# STM32F302 register map
File version: 1.8
CPU: CM4 r1p0, little endian, MPU, FPU, 4 interrupt priority bits
Registers are 32-bit, read-write, reset 0x0 unless marked. A register's access mark holds for its fields unless they carry their own. Offsets are from the block's base; [hi:lo] are bit positions; lines under a group give offsets from that group; {n}, {i} and the like mark numbered series; 'fields as' and 'values as' point back to an identical list; <NAME> marks a mode.

## FLASH
Base 0x40022000
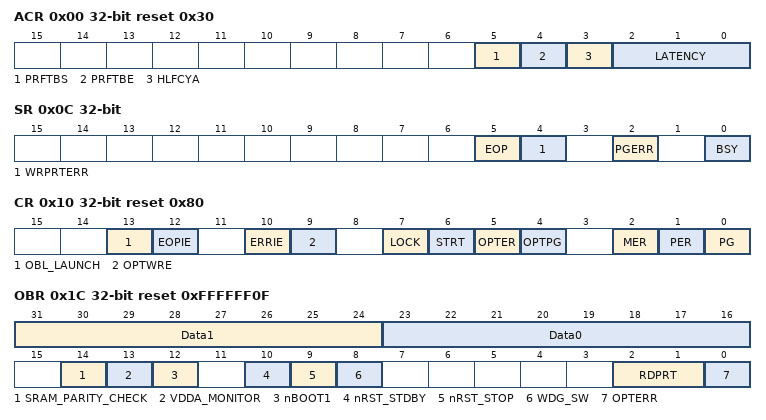
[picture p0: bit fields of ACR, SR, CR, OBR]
0x00 ACR access per field reset 0x30 — Flash access control register
  [5] PRFTBS ro
    0=Disabled (Prefetch buffer is disabled); 1=Enabled (Prefetch buffer is enabled)
  [4] PRFTBE rw
    0=Disabled (Prefetch is disabled); 1=Enabled (Prefetch is enabled)
  [3] HLFCYA rw — Flash half cycle access enable
    0=Disabled (Half cycle is disabled); 1=Enabled (Half cycle is enabled)
  [2:0] LATENCY rw
    0=WS0 (0 wait states, if 0 < HCLK <= 24 MHz); 1=WS1 (1 wait state, if 24 < HCLK <= 48 MHz); 2=WS2 (2 wait states, if 48 < HCLK <= 72 MHz)
0x04 KEYR wo — Flash key register
  [31:0] FKEYR — Flash Key
0x08 OPTKEYR wo — Flash option key register
  [31:0] OPTKEYR — Option byte key
0x0C SR access per field — Flash status register
  [5] EOP rw — End of operation
    on read: 0=NoEvent (No EOP event occurred); 1=Event (An EOP event occurred) | on write: 1=Reset EOP event
  [4] WRPRTERR rw — Write protection error
    on read: 0=NoError (No write protection error occurred); 1=Error (A write protection error occurred) | on write: 1=Reset write protection error
  [2] PGERR rw — Programming error
    on read: 0=NoError (No programming error occurred); 1=Error (A programming error occurred) | on write: 1=Reset programming error
  [0] BSY ro — Busy
    0=Inactive (No write/erase operation is in progress); 1=Active (No write/erase operation is in progress)
0x10 CR reset 0x80 — Flash control register
  [13] OBL_LAUNCH — Force option byte loading
    0=Inactive (Force option byte loading inactive); 1=Active (Force option byte loading active)
  [12] EOPIE — End of operation interrupt enable
    0=Disabled (End of operation interrupt disabled); 1=Enabled (End of operation interrupt enabled)
  [10] ERRIE — Error interrupt enable
    0=Disabled (Error interrupt generation disabled); 1=Enabled (Error interrupt generation enabled)
  [9] OPTWRE — Option bytes write enable
    0=Disabled (Option byte write enabled); 1=Enabled (Option byte write disabled)
  [7] LOCK
    on read: 0=Unlocked (FLASH_CR register is unlocked); 1=Locked (FLASH_CR register is locked) | on write: 1=Lock the FLASH_CR register
  [6] STRT — Start
    1=Start (Trigger an erase operation)
  [5] OPTER — Option byte erase
    1=OptionByteErase (Erase option byte activated)
  [4] OPTPG — Option byte programming
    1=OptionByteProgramming (Program option byte activated)
  [2] MER — Mass erase
    1=MassErase (Erase activated for all user sectors)
  [1] PER — Page erase
    1=PageErase (Erase activated for selected page)
  [0] PG — Programming
    1=Program (Flash programming activated)
0x14 AR wo — Flash address register
  [31:0] FAR — Flash address
0x1C OBR ro reset 0xFFFFFF0F — Option byte register
  [31:24] Data1
  [23:16] Data0
  [14] SRAM_PARITY_CHECK
    0=Disabled (RAM parity check disabled); 1=Enabled (RAM parity check enabled)
  [13] VDDA_MONITOR
    0=Disabled (VDDA power supply supervisor disabled); 1=Enabled (VDDA power supply supervisor enabled)
  [12] nBOOT1 — BOOT1
    0=Disabled (Together with BOOT0, select the device boot mode); 1=Enabled (Together with BOOT0, select the device boot mode)
  [10] nRST_STDBY
    0=Reset generated when entering Standby mode; 1=No reset generated
  [9] nRST_STOP
    0=Reset generated when entering Stop mode; 1=No reset generated
  [8] WDG_SW
    0=Hardware watchdog; 1=Software watchdog
  [2:1] RDPRT — Read protection Level status
    0=Level0; 1=Level1; 3=Level2
  [0] OPTERR — Option byte error
    1=OptionByteError (The loaded option byte and its complement do not match)
0x20 WRPR ro reset 0xFFFFFFFF — Write protection register
  [31:0] WRP — Write protect

## DMA1 — DMA controller 1
Base 0x40020000
Same registers: DMA2 0x40020400
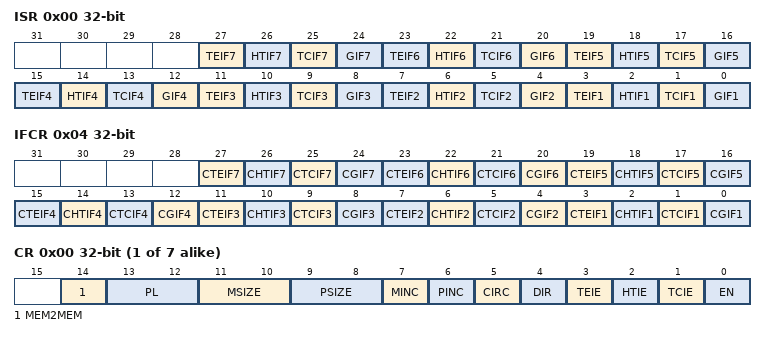
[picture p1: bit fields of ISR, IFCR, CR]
0x00 ISR ro — DMA interrupt status register (DMA_ISR)
  [4n-1] TEIF{n} (n=1..7) — Channel {n} Transfer Error flag
    0=NoError (No transfer error); 1=Error (A transfer error has occured)
  [4n-2] HTIF{n} (n=1..7) — Channel {n} Half Transfer Complete flag
    0=NotHalf (No half transfer event); 1=Half (A half transfer event has occured)
  [4n-3] TCIF{n} (n=1..7) — Channel {n} Transfer Complete flag
    0=NotComplete (No transfer complete event); 1=Complete (A transfer complete event has occured)
  [4n-4] GIF{n} (n=1..7) — Channel {n} Global interrupt flag
    0=NoEvent (No transfer error, half event, complete event); 1=Event (A transfer error, half event or complete event has occured)
0x04 IFCR wo — DMA interrupt flag clear register (DMA_IFCR)
  [4n-1] CTEIF{n} (n=1..7) — Channel {n} Transfer Error clear
    1=Clears the TEIF flag in the ISR register
  [4n-2] CHTIF{n} (n=1..7) — Channel {n} Half Transfer clear
    1=Clears the HTIF flag in the ISR register
  [4n-3] CTCIF{n} (n=1..7) — Channel {n} Transfer Complete clear
    1=Clears the TCIF flag in the ISR register
  [4n-4] CGIF{n} (n=1..7) — Channel {n} Global interrupt clear
    1=Clears the GIF, TEIF, HTIF, TCIF flags in the ISR register
0x08 CH{i} (i=1..7; step 0x14) group — Channel cluster: CCR?, CNDTR?, CPAR?, and CMAR? registers
  0x00 CR — DMA channel configuration register (DMA_CCR)
    [14] MEM2MEM — Memory to memory mode
      0=Disabled (Memory to memory mode disabled); 1=Enabled (Memory to memory mode enabled)
    [13:12] PL — Channel Priority level
      0=Low (Low priority); 1=Medium priority; 2=High priority; 3=Very high priority
    [11:10] MSIZE — Memory size
      0=Bits8 (8-bit size); 1=Bits16 (16-bit size); 2=Bits32 (32-bit size)
    [9:8] PSIZE — Peripheral size
      values as MSIZE
    [7] MINC — Memory increment mode
      0=Disabled (Increment mode disabled); 1=Enabled (Increment mode enabled)
    [6] PINC — Peripheral increment mode
      values as MINC
    [5] CIRC — Circular mode
      0=Disabled (Circular buffer disabled); 1=Enabled (Circular buffer enabled)
    [4] DIR — Data transfer direction
      0=FromPeripheral (Read from peripheral); 1=FromMemory (Read from memory)
    [3] TEIE — Transfer error interrupt enable
      0=Disabled (Transfer Error interrupt disabled); 1=Enabled (Transfer Error interrupt enabled)
    [2] HTIE — Half Transfer interrupt enable
      0=Disabled (Half Transfer interrupt disabled); 1=Enabled (Half Transfer interrupt enabled)
    [1] TCIE — Transfer complete interrupt enable
      0=Disabled (Transfer Complete interrupt disabled); 1=Enabled (Transfer Complete interrupt enabled)
    [0] EN — Channel enable
      0=Disabled (Channel disabled); 1=Enabled (Channel enabled)
  0x04 NDTR — DMA channel 1 number of data register
    [15:0] NDT — Number of data to transfer
  0x08 PAR — DMA channel 1 peripheral address register
    [31:0] PA — Peripheral address
  0x0C MAR — DMA channel 1 memory address register
    [31:0] MA — Memory address
